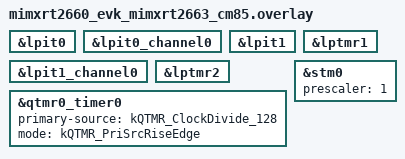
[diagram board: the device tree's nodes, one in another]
/*
 * SPDX-FileCopyrightText: Copyright 2026 NXP
 *
 * SPDX-License-Identifier: Apache-2.0
 */

&lpit0 {
	status = "okay";
};

&lpit0_channel0 {
	status = "okay";
};

&lpit1 {
	status = "okay";
};

&lpit1_channel0 {
	status = "okay";
};

&lptmr1 {
	status = "okay";
};

&lptmr2 {
	status = "okay";
};

&qtmr0_timer0 {
	status = "okay";
	primary-source = "kQTMR_ClockDivide_128";
	mode = "kQTMR_PriSrcRiseEdge";
};

&stm0 {
	prescaler = <1>;
	status = "okay";
};
